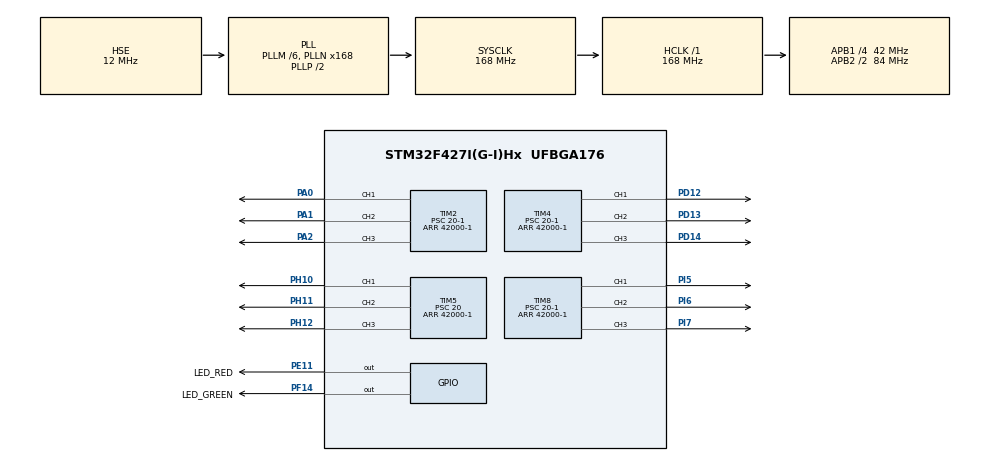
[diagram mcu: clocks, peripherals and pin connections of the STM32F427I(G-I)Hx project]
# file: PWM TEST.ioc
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Mcu.Family=STM32F4
Mcu.Name=STM32F427I(G-I)Hx
Mcu.Package=UFBGA176
Mcu.UserConstants=TIM_PSC_APB1,((APB1_TIMER_CLOCKS/PWM_FREQUENCE)/PWM_RESOLUTION -1);PWM_FREQUENCE,50;PWM_RESOLUTION,10000;APB1_TIMER_CLOCKS,84000000;PWM_DEFAULT_DUTY,5000;TIM_PSC_APB2,((APB2_TIMER_CLOCKS/PWM_FREQUENCE)/PWM_RESOLUTION -1);APB2_TIMER_CLOCKS,168000000
NVIC.PriorityGroup=NVIC_PRIORITYGROUP_4
PA0/WKUP.Signal=S_TIM2_CH1_ETR
PA1.Signal=S_TIM2_CH2
PA2.Signal=S_TIM2_CH3
PD12.Signal=S_TIM4_CH1
PD13.Signal=S_TIM4_CH2
PD14.Signal=S_TIM4_CH3
PD15.Signal=S_TIM4_CH4
PE11.GPIO_Label=LED_RED
PE11.Signal=GPIO_Output
PF14.GPIO_Label=LED_GREEN
PF14.Signal=GPIO_Output
PH0/OSC_IN.Mode=HSE-External-Oscillator
PH0/OSC_IN.Signal=RCC_OSC_IN
PH1/OSC_OUT.Mode=HSE-External-Oscillator
PH1/OSC_OUT.Signal=RCC_OSC_OUT
PH10.Signal=S_TIM5_CH1
PH11.Signal=S_TIM5_CH2
PH12.Signal=S_TIM5_CH3
PI0.Signal=S_TIM5_CH4
PI2.Signal=S_TIM8_CH4
PI5.Signal=S_TIM8_CH1
PI6.Signal=S_TIM8_CH2
PI7.Signal=S_TIM8_CH3
ProjectManager.HeapSize=0x200
ProjectManager.StackSize=0x400
ProjectManager.TargetToolchain=TrueSTUDIO
RCC.48MHZClocksFreq_Value=84000000
RCC.AHBFreq_Value=168000000
RCC.APB1CLKDivider=RCC_HCLK_DIV4
RCC.APB1Freq_Value=42000000
RCC.APB1TimFreq_Value=84000000
RCC.APB2CLKDivider=RCC_HCLK_DIV2
RCC.APB2Freq_Value=84000000
RCC.APB2TimFreq_Value=168000000
RCC.CortexFreq_Value=168000000
RCC.HCLKFreq_Value=168000000
RCC.HSE_VALUE=12000000
RCC.HSI_VALUE=16000000
RCC.LSE_VALUE=32768
RCC.PLLM=6
RCC.PLLN=168
RCC.PLLSourceVirtual=RCC_PLLSOURCE_HSE
RCC.SYSCLKFreq_VALUE=168000000
RCC.SYSCLKSource=RCC_SYSCLKSOURCE_PLLCLK
RCC.VCOOutputFreq_Value=336000000
SH.S_TIM2_CH1_ETR.0=TIM2_CH1,PWM Generation1 CH1
SH.S_TIM2_CH2.0=TIM2_CH2,PWM Generation2 CH2
SH.S_TIM2_CH3.0=TIM2_CH3,PWM Generation3 CH3
SH.S_TIM4_CH1.0=TIM4_CH1,PWM Generation1 CH1
SH.S_TIM4_CH2.0=TIM4_CH2,PWM Generation2 CH2
SH.S_TIM4_CH3.0=TIM4_CH3,PWM Generation3 CH3
SH.S_TIM4_CH4.0=TIM4_CH4
SH.S_TIM5_CH1.0=TIM5_CH1,PWM Generation1 CH1
SH.S_TIM5_CH2.0=TIM5_CH2,PWM Generation2 CH2
SH.S_TIM5_CH3.0=TIM5_CH3,PWM Generation3 CH3
SH.S_TIM5_CH4.0=TIM5_CH4
SH.S_TIM8_CH1.0=TIM8_CH1,PWM Generation1 CH1
SH.S_TIM8_CH2.0=TIM8_CH2,PWM Generation2 CH2
SH.S_TIM8_CH3.0=TIM8_CH3,PWM Generation3 CH3
SH.S_TIM8_CH4.0=TIM8_CH4
TIM2.Channel-Output\ Compare4\ No\ Output=TIM_CHANNEL_4
TIM2.Channel-PWM\ Generation1\ CH1=TIM_CHANNEL_1
TIM2.Channel-PWM\ Generation2\ CH2=TIM_CHANNEL_2
TIM2.Channel-PWM\ Generation3\ CH3=TIM_CHANNEL_3
TIM2.Period=42000-1
TIM2.Prescaler=20-1
TIM2.Pulse-PWM\ Generation1\ CH1=21000-1
TIM2.Pulse-PWM\ Generation2\ CH2=10500-1
TIM2.Pulse-PWM\ Generation3\ CH3=5250-1
TIM4.Channel-PWM\ Generation1\ CH1=TIM_CHANNEL_1
TIM4.Channel-PWM\ Generation2\ CH2=TIM_CHANNEL_2
TIM4.Channel-PWM\ Generation3\ CH3=TIM_CHANNEL_3
TIM4.Channel-PWM\ Generation4\ No\ Output=TIM_CHANNEL_4
TIM4.Period=42000-1
TIM4.Prescaler=20-1
TIM4.Pulse-PWM\ Generation1\ CH1=21000-1
TIM4.Pulse-PWM\ Generation2\ CH2=10500-1
TIM4.Pulse-PWM\ Generation3\ CH3=5250-1
TIM5.Channel-Output\ Compare4\ No\ Output=TIM_CHANNEL_4
TIM5.Channel-PWM\ Generation1\ CH1=TIM_CHANNEL_1
TIM5.Channel-PWM\ Generation2\ CH2=TIM_CHANNEL_2
TIM5.Channel-PWM\ Generation3\ CH3=TIM_CHANNEL_3
TIM5.Period=42000-1
TIM5.Prescaler=20
TIM5.Pulse-PWM\ Generation1\ CH1=21000-1
TIM5.Pulse-PWM\ Generation2\ CH2=10500-1
TIM5.Pulse-PWM\ Generation3\ CH3=5250-1
TIM8.Channel-Output\ Compare4\ No\ Output=TIM_CHANNEL_4
TIM8.Channel-PWM\ Generation1\ CH1=TIM_CHANNEL_1
TIM8.Channel-PWM\ Generation2\ CH2=TIM_CHANNEL_2
TIM8.Channel-PWM\ Generation3\ CH3=TIM_CHANNEL_3
TIM8.Period=42000-1
TIM8.Prescaler=20-1
TIM8.Pulse-PWM\ Generation1\ CH1=21000-1
TIM8.Pulse-PWM\ Generation2\ CH2=10500-1
TIM8.Pulse-PWM\ Generation3\ CH3=5250-1
VP_TIM2_VS_ClockSourceINT.Mode=Internal
VP_TIM2_VS_no_output4.Mode=Output Compare4 No Output
VP_TIM4_VS_ClockSourceINT.Mode=Internal
VP_TIM4_VS_no_output4.Mode=PWM Generation4 No Output
VP_TIM5_VS_ClockSourceINT.Mode=Internal
VP_TIM5_VS_no_output4.Mode=Output Compare4 No Output
VP_TIM8_VS_ClockSourceINT.Mode=Internal
VP_TIM8_VS_no_output4.Mode=Output Compare4 No Output
board=PWM

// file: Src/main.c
/**
  ******************************************************************************
  * @file           : main.c
  * @brief          : Main program body
  ******************************************************************************
  ** This notice applies to any and all portions of this file
  * that are not between comment pairs USER CODE BEGIN and
  * USER CODE END. Other portions of this file, whether
  * inserted by the user or by software development tools
  * are owned by their respective copyright owners.
  *
  * COPYRIGHT(c) 2019 STMicroelectronics
  *
  * Redistribution and use in source and binary forms, with or without modification,
  * are permitted provided that the following conditions are met:
  *   1. Redistributions of source code must retain the above copyright notice,
  *      this list of conditions and the following disclaimer.
  *   2. Redistributions in binary form must reproduce the above copyright notice,
  *      this list of conditions and the following disclaimer in the documentation
  *      and/or other materials provided with the distribution.
  *   3. Neither the name of STMicroelectronics nor the names of its contributors
  *      may be used to endorse or promote products derived from this software
  *      without specific prior written permission.
  *
  * THIS SOFTWARE IS PROVIDED BY THE COPYRIGHT HOLDERS AND CONTRIBUTORS "AS IS"
  * AND ANY EXPRESS OR IMPLIED WARRANTIES, INCLUDING, BUT NOT LIMITED TO, THE
  * IMPLIED WARRANTIES OF MERCHANTABILITY AND FITNESS FOR A PARTICULAR PURPOSE ARE
  * DISCLAIMED. IN NO EVENT SHALL THE COPYRIGHT HOLDER OR CONTRIBUTORS BE LIABLE
  * FOR ANY DIRECT, INDIRECT, INCIDENTAL, SPECIAL, EXEMPLARY, OR CONSEQUENTIAL
  * DAMAGES (INCLUDING, BUT NOT LIMITED TO, PROCUREMENT OF SUBSTITUTE GOODS OR
  * SERVICES; LOSS OF USE, DATA, OR PROFITS; OR BUSINESS INTERRUPTION) HOWEVER
  * CAUSED AND ON ANY THEORY OF LIABILITY, WHETHER IN CONTRACT, STRICT LIABILITY,
  * OR TORT (INCLUDING NEGLIGENCE OR OTHERWISE) ARISING IN ANY WAY OUT OF THE USE
  * OF THIS SOFTWARE, EVEN IF ADVISED OF THE POSSIBILITY OF SUCH DAMAGE.
  *
  ******************************************************************************
  */
#include "main.h"
#include "stm32f4xx_hal.h"
#include "tim.h"
#include "gpio.h"

/* USER CODE BEGIN PV */
/* Private variables ---------------------------------------------------------*/

/* USER CODE END PV */

void SystemClock_Config(void);

/* USER CODE BEGIN PFP */
/* Private function prototypes -----------------------------------------------*/

/* USER CODE END PFP */

int main(void)
{

  /* MCU Configuration----------------------------------------------------------*/

  /* Reset of all peripherals, Initializes the Flash interface and the Systick. */
  HAL_Init();

  /* Configure the system clock */
  SystemClock_Config();

  /* Initialize all configured peripherals */
  MX_GPIO_Init();
  MX_TIM2_Init();
  MX_TIM4_Init();
  MX_TIM5_Init();
  MX_TIM8_Init();
  /* USER CODE BEGIN 2 */
  HAL_TIM_PWM_Start(&htim2,TIM_CHANNEL_1);
  HAL_TIM_PWM_Start(&htim2,TIM_CHANNEL_2);
  HAL_TIM_PWM_Start(&htim2,TIM_CHANNEL_3);

  HAL_TIM_PWM_Start(&htim4,TIM_CHANNEL_1);
  HAL_TIM_PWM_Start(&htim4,TIM_CHANNEL_2);
  HAL_TIM_PWM_Start(&htim4,TIM_CHANNEL_3);

  HAL_TIM_PWM_Start(&htim5,TIM_CHANNEL_1);
  HAL_TIM_PWM_Start(&htim5,TIM_CHANNEL_2);
  HAL_TIM_PWM_Start(&htim5,TIM_CHANNEL_3);

  HAL_TIM_PWM_Start(&htim8,TIM_CHANNEL_1);
  HAL_TIM_PWM_Start(&htim8,TIM_CHANNEL_2);
  HAL_TIM_PWM_Start(&htim8,TIM_CHANNEL_3);
  /* USER CODE END 2 */

  /* Infinite loop */
  while (1)
  {

  }

}

void SystemClock_Config(void)
{

  RCC_OscInitTypeDef RCC_OscInitStruct;
  RCC_ClkInitTypeDef RCC_ClkInitStruct;

    /**Configure the main internal regulator output voltage
    */
  __HAL_RCC_PWR_CLK_ENABLE();

  __HAL_PWR_VOLTAGESCALING_CONFIG(PWR_REGULATOR_VOLTAGE_SCALE1);

    /**Initializes the CPU, AHB and APB busses clocks
    */
  RCC_OscInitStruct.OscillatorType = RCC_OSCILLATORTYPE_HSE;
  RCC_OscInitStruct.HSEState = RCC_HSE_ON;
  RCC_OscInitStruct.PLL.PLLState = RCC_PLL_ON;
  RCC_OscInitStruct.PLL.PLLSource = RCC_PLLSOURCE_HSE;
  RCC_OscInitStruct.PLL.PLLM = 6;
  RCC_OscInitStruct.PLL.PLLN = 168;
  RCC_OscInitStruct.PLL.PLLP = RCC_PLLP_DIV2;
  RCC_OscInitStruct.PLL.PLLQ = 4;
  if (HAL_RCC_OscConfig(&RCC_OscInitStruct) != HAL_OK)
  {
    _Error_Handler(__FILE__, __LINE__);
  }

    /**Initializes the CPU, AHB and APB busses clocks
    */
  RCC_ClkInitStruct.ClockType = RCC_CLOCKTYPE_HCLK|RCC_CLOCKTYPE_SYSCLK
                              |RCC_CLOCKTYPE_PCLK1|RCC_CLOCKTYPE_PCLK2;
  RCC_ClkInitStruct.SYSCLKSource = RCC_SYSCLKSOURCE_PLLCLK;
  RCC_ClkInitStruct.AHBCLKDivider = RCC_SYSCLK_DIV1;
  RCC_ClkInitStruct.APB1CLKDivider = RCC_HCLK_DIV4;
  RCC_ClkInitStruct.APB2CLKDivider = RCC_HCLK_DIV2;

  if (HAL_RCC_ClockConfig(&RCC_ClkInitStruct, FLASH_LATENCY_5) != HAL_OK)
  {
    _Error_Handler(__FILE__, __LINE__);
  }

    /**Configure the Systick interrupt time
    */
  HAL_SYSTICK_Config(HAL_RCC_GetHCLKFreq()/1000);

    /**Configure the Systick
    */
  HAL_SYSTICK_CLKSourceConfig(SYSTICK_CLKSOURCE_HCLK);

  /* SysTick_IRQn interrupt configuration */
  HAL_NVIC_SetPriority(SysTick_IRQn, 0, 0);
}

void _Error_Handler(char *file, int line)
{
  while(1)
  {
  }
}

/************************ (C) COPYRIGHT STMicroelectronics *****END OF FILE****/
